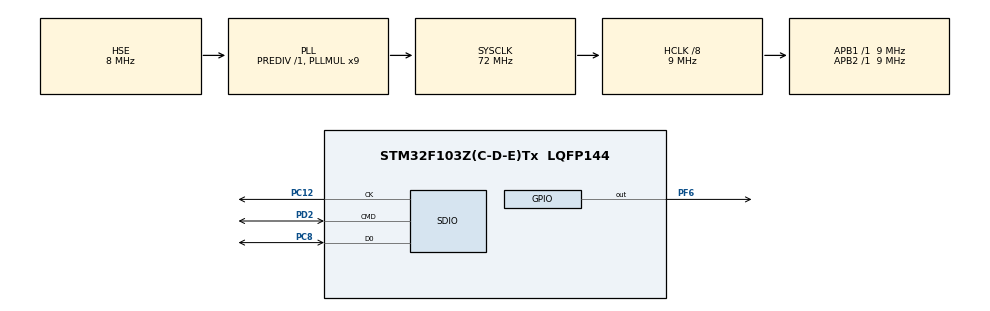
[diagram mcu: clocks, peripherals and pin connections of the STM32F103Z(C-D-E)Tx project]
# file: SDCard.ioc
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FATFS._USE_MKFS=0
FATFS._USE_STRFUNC=1
Mcu.Family=STM32F1
Mcu.Name=STM32F103Z(C-D-E)Tx
Mcu.Package=LQFP144
NVIC.PriorityGroup=NVIC_PRIORITYGROUP_4
OSC_IN.Mode=HSE-External-Oscillator
OSC_IN.Signal=RCC_OSC_IN
OSC_OUT.Mode=HSE-External-Oscillator
OSC_OUT.Signal=RCC_OSC_OUT
PC12.GPIO_Speed_High_Default=GPIO_SPEED_FREQ_LOW
PC12.Mode=SD_1_bit
PC12.Signal=SDIO_CK
PC8.GPIO_Speed_High_Default=GPIO_SPEED_FREQ_LOW
PC8.Mode=SD_1_bit
PC8.Signal=SDIO_D0
PD2.GPIO_Speed_High_Default=GPIO_SPEED_FREQ_LOW
PD2.Mode=SD_1_bit
PD2.Signal=SDIO_CMD
PF6.Signal=GPIO_Output
ProjectManager.HeapSize=0x2000
ProjectManager.StackSize=0x4000
ProjectManager.TargetToolchain=MDK-ARM V5
RCC.AHBCLKDivider=RCC_SYSCLK_DIV8
RCC.AHBFreq_Value=9000000
RCC.APB1Freq_Value=9000000
RCC.APB1TimFreq_Value=9000000
RCC.APB2Freq_Value=9000000
RCC.APB2TimFreq_Value=9000000
RCC.HCLKFreq_Value=9000000
RCC.PLLMUL=RCC_PLL_MUL9
RCC.PLLSourceVirtual=RCC_PLLSOURCE_HSE
RCC.SYSCLKFreq_VALUE=72000000
RCC.SYSCLKSource=RCC_SYSCLKSOURCE_PLLCLK
RCC.USBFreq_Value=72000000
VP_FATFS_VS_SDIO.Mode=SDIO
VP_SYS_VS_ND.Mode=No_Debug
board=custom

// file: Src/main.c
/* USER CODE BEGIN Header */
/**
  ******************************************************************************
  * @file           : main.c
  * @brief          : Main program body
  ******************************************************************************
  * This notice applies to any and all portions of this file
  * that are not between comment pairs USER CODE BEGIN and
  * USER CODE END. Other portions of this file, whether
  * inserted by the user or by software development tools
  * are owned by their respective copyright owners.
  *
  * Copyright (c) 2019 STMicroelectronics International N.V.
  * All rights reserved.
  *
  * Redistribution and use in source and binary forms, with or without
  * modification, are permitted, provided that the following conditions are met:
  *
  * 1. Redistribution of source code must retain the above copyright notice,
  *    this list of conditions and the following disclaimer.
  * 2. Redistributions in binary form must reproduce the above copyright notice,
  *    this list of conditions and the following disclaimer in the documentation
  *    and/or other materials provided with the distribution.
  * 3. Neither the name of STMicroelectronics nor the names of other
  *    contributors to this software may be used to endorse or promote products
  *    derived from this software without specific written permission.
  * 4. This software, including modifications and/or derivative works of this
  *    software, must execute solely and exclusively on microcontroller or
  *    microprocessor devices manufactured by or for STMicroelectronics.
  * 5. Redistribution and use of this software other than as permitted under
  *    this license is void and will automatically terminate your rights under
  *    this license.
  *
  * THIS SOFTWARE IS PROVIDED BY STMICROELECTRONICS AND CONTRIBUTORS "AS IS"
  * AND ANY EXPRESS, IMPLIED OR STATUTORY WARRANTIES, INCLUDING, BUT NOT
  * LIMITED TO, THE IMPLIED WARRANTIES OF MERCHANTABILITY, FITNESS FOR A
  * PARTICULAR PURPOSE AND NON-INFRINGEMENT OF THIRD PARTY INTELLECTUAL PROPERTY
  * RIGHTS ARE DISCLAIMED TO THE FULLEST EXTENT PERMITTED BY LAW. IN NO EVENT
  * SHALL STMICROELECTRONICS OR CONTRIBUTORS BE LIABLE FOR ANY DIRECT, INDIRECT,
  * INCIDENTAL, SPECIAL, EXEMPLARY, OR CONSEQUENTIAL DAMAGES (INCLUDING, BUT NOT
  * LIMITED TO, PROCUREMENT OF SUBSTITUTE GOODS OR SERVICES; LOSS OF USE, DATA,
  * OR PROFITS; OR BUSINESS INTERRUPTION) HOWEVER CAUSED AND ON ANY THEORY OF
  * LIABILITY, WHETHER IN CONTRACT, STRICT LIABILITY, OR TORT (INCLUDING
  * NEGLIGENCE OR OTHERWISE) ARISING IN ANY WAY OUT OF THE USE OF THIS SOFTWARE,
  * EVEN IF ADVISED OF THE POSSIBILITY OF SUCH DAMAGE.
  *
  ******************************************************************************
  */
/* USER CODE END Header */

#include "main.h"
#include "fatfs.h"

SD_HandleTypeDef hsd;

/* USER CODE BEGIN PV */
FATFS fatfs;
FIL myfile;
FRESULT fresult;
/* USER CODE END PV */

void SystemClock_Config(void);
static void MX_GPIO_Init(void);
static void MX_SDIO_SD_Init(void);

int main(void)
{
  /* USER CODE BEGIN 1 */
	int i = 0;
  /* USER CODE END 1 */

  /* MCU Configuration--------------------------------------------------------*/

  /* Reset of all peripherals, Initializes the Flash interface and the Systick. */
  HAL_Init();

  /* Configure the system clock */
  SystemClock_Config();

  /* Initialize all configured peripherals */
  MX_GPIO_Init();
  MX_SDIO_SD_Init();
  MX_FATFS_Init();
	if( BSP_SD_Init()  == MSD_OK ) {
		fresult = f_mount( &fatfs , "" , 1 );
		fresult = f_open( &myfile , "yah.txt" , FA_CREATE_ALWAYS | FA_WRITE );
		f_printf( &myfile , "hi , i work truely" );
		f_close( &myfile );
	}
  /* Infinite loop */
  while (1)
  {
		HAL_GPIO_WritePin(GPIOF, GPIO_PIN_6, GPIO_PIN_RESET);
		//for( i = 0 ; i < 100000 ; i ++ );
		HAL_GPIO_WritePin(GPIOF, GPIO_PIN_6, GPIO_PIN_SET);
		//for( i = 0 ; i < 100000 ; i ++ );
  }
}

void SystemClock_Config(void)
{
  RCC_OscInitTypeDef RCC_OscInitStruct = {0};
  RCC_ClkInitTypeDef RCC_ClkInitStruct = {0};

  /**Initializes the CPU, AHB and APB busses clocks
  */
  RCC_OscInitStruct.OscillatorType = RCC_OSCILLATORTYPE_HSE;
  RCC_OscInitStruct.HSEState = RCC_HSE_ON;
  RCC_OscInitStruct.HSEPredivValue = RCC_HSE_PREDIV_DIV1;
  RCC_OscInitStruct.HSIState = RCC_HSI_ON;
  RCC_OscInitStruct.PLL.PLLState = RCC_PLL_ON;
  RCC_OscInitStruct.PLL.PLLSource = RCC_PLLSOURCE_HSE;
  RCC_OscInitStruct.PLL.PLLMUL = RCC_PLL_MUL9;
  if (HAL_RCC_OscConfig(&RCC_OscInitStruct) != HAL_OK)
  {
    Error_Handler();
  }
  /**Initializes the CPU, AHB and APB busses clocks
  */
  RCC_ClkInitStruct.ClockType = RCC_CLOCKTYPE_HCLK|RCC_CLOCKTYPE_SYSCLK
                              |RCC_CLOCKTYPE_PCLK1|RCC_CLOCKTYPE_PCLK2;
  RCC_ClkInitStruct.SYSCLKSource = RCC_SYSCLKSOURCE_PLLCLK;
  RCC_ClkInitStruct.AHBCLKDivider = RCC_SYSCLK_DIV8;
  RCC_ClkInitStruct.APB1CLKDivider = RCC_HCLK_DIV1;
  RCC_ClkInitStruct.APB2CLKDivider = RCC_HCLK_DIV1;

  if (HAL_RCC_ClockConfig(&RCC_ClkInitStruct, FLASH_LATENCY_2) != HAL_OK)
  {
    Error_Handler();
  }
}

static void MX_SDIO_SD_Init(void)
{

  hsd.Instance = SDIO;
  hsd.Init.ClockEdge = SDIO_CLOCK_EDGE_RISING;
  hsd.Init.ClockBypass = SDIO_CLOCK_BYPASS_DISABLE;
  hsd.Init.ClockPowerSave = SDIO_CLOCK_POWER_SAVE_DISABLE;
  hsd.Init.BusWide = SDIO_BUS_WIDE_1B;
  hsd.Init.HardwareFlowControl = SDIO_HARDWARE_FLOW_CONTROL_DISABLE;
  hsd.Init.ClockDiv = 0;

}

static void MX_GPIO_Init(void)
{
  GPIO_InitTypeDef GPIO_InitStruct = {0};

  /* GPIO Ports Clock Enable */
  __HAL_RCC_GPIOF_CLK_ENABLE();
  __HAL_RCC_GPIOC_CLK_ENABLE();
  __HAL_RCC_GPIOD_CLK_ENABLE();

  /*Configure GPIO pin Output Level */
  HAL_GPIO_WritePin(GPIOF, GPIO_PIN_6, GPIO_PIN_RESET);

  /*Configure GPIO pin : PF6 */
  GPIO_InitStruct.Pin = GPIO_PIN_6;
  GPIO_InitStruct.Mode = GPIO_MODE_OUTPUT_PP;
  GPIO_InitStruct.Pull = GPIO_NOPULL;
  GPIO_InitStruct.Speed = GPIO_SPEED_FREQ_LOW;
  HAL_GPIO_Init(GPIOF, &GPIO_InitStruct);

}

void Error_Handler(void)
{
}

/************************ (C) COPYRIGHT STMicroelectronics *****END OF FILE****/
